# L3INIT_CM2 register map
Vendor: Texas Instruments
Peripheral module from a debugger description file (folder omap4460).
Registers are 32-bit, access per field, reset 0x70000 unless marked. A register's access mark holds for its fields unless they carry their own. Offsets are as the file gives them; lines under a group give offsets from that group; [hi:lo] are bit positions; {n}, {i} and the like mark numbered series; 'fields as' and 'values as' point back to an identical list; <NAME> marks a mode.

## L3INIT_CM2
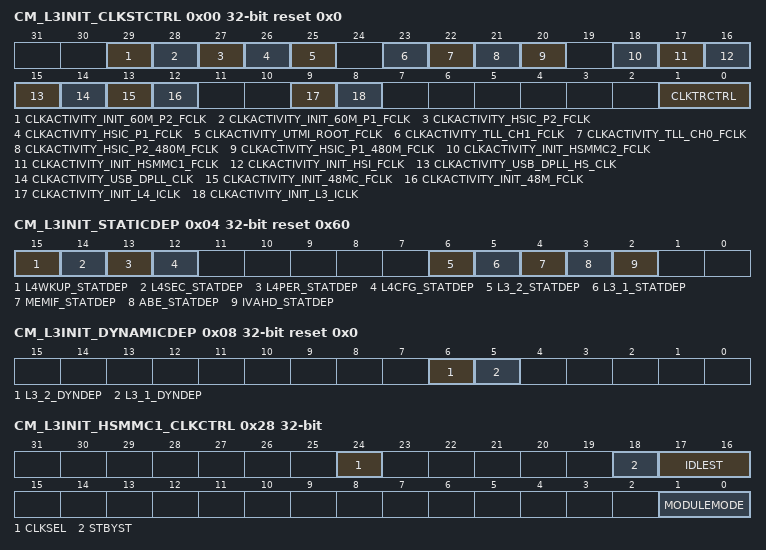
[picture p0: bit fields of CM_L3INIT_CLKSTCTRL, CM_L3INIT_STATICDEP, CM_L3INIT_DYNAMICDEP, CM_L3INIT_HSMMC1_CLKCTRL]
0x00 CM_L3INIT_CLKSTCTRL reset 0x0 — This register enables the domain power state transition. It controls the hardware supervised domain power state transition between ON-ACTIVE and ON-INACTIVE states. It also holds 1 status bit per clock input of the domain.
  [29] CLKACTIVITY_INIT_60M_P2_FCLK ro — This field indicates the state of the INIT_60M_P2_FCLK clock in the domain. [warm reset insensitive]
    0=CLKACTIVITY_INIT_60M_P2_FCLK_0_r (Corresponding clock is definitely gated); 1=CLKACTIVITY_INIT_60M_P2_FCLK_1_r (Corresponding clock is running or gating/ungating transition is ongoing)
  [28] CLKACTIVITY_INIT_60M_P1_FCLK ro — This field indicates the state of the INIT_60M_P1_FCLK clock in the domain. [warm reset insensitive]
    0=CLKACTIVITY_INIT_60M_P1_FCLK_0_r (Corresponding clock is definitely gated); 1=CLKACTIVITY_INIT_60M_P1_FCLK_1_r (Corresponding clock is running or gating/ungating transition is ongoing)
  [27] CLKACTIVITY_HSIC_P2_FCLK ro — This field indicates the state of the HSIC_P2_FCLK clock in the domain. [warm reset insensitive]
    0=CLKACTIVITY_HSIC_P2_FCLK_0_r (Corresponding clock is definitely gated); 1=CLKACTIVITY_HSIC_P2_FCLK_1_r (Corresponding clock is running or gating/ungating transition is ongoing)
  [26] CLKACTIVITY_HSIC_P1_FCLK ro — This field indicates the state of the HSIC_P1_FCLK clock in the domain. [warm reset insensitive]
    0=CLKACTIVITY_HSIC_P1_FCLK_0_r (Corresponding clock is definitely gated); 1=CLKACTIVITY_HSIC_P1_FCLK_1_r (Corresponding clock is running or gating/ungating transition is ongoing)
  [25] CLKACTIVITY_UTMI_ROOT_FCLK ro — This field indicates the state of the UTMI_ROOT_FCLK clock in the domain. [warm reset insensitive]
    0=CLKACTIVITY_UTMI_ROOT_FCLK_0_r (Corresponding clock is definitely gated); 1=CLKACTIVITY_UTMI_ROOT_FCLK_1_r (Corresponding clock is running or gating/ungating transition is ongoing)
  [23] CLKACTIVITY_TLL_CH1_FCLK ro — This field indicates the state of the TLL_CH1_FCLK clock in the domain. [warm reset insensitive]
    0=CLKACTIVITY_TLL_CH1_FCLK_0_r (Corresponding clock is definitely gated); 1=CLKACTIVITY_TLL_CH1_FCLK_1_r (Corresponding clock is running or gating/ungating transition is ongoing)
  [22] CLKACTIVITY_TLL_CH0_FCLK ro — This field indicates the state of the TLL_CH0_FCLK clock in the domain. [warm reset insensitive]
    0=CLKACTIVITY_TLL_CH0_FCLK_0_r (Corresponding clock is definitely gated); 1=CLKACTIVITY_TLL_CH0_FCLK_1_r (Corresponding clock is running or gating/ungating transition is ongoing)
  [21] CLKACTIVITY_HSIC_P2_480M_FCLK ro — This field indicates the state of the HSIC_P2_480M_FCLK clock in the domain. [warm reset insensitive]
    0=CLKACTIVITY_HSIC_P2_480M_FCLK_0_r (Corresponding clock is definitely gated); 1=CLKACTIVITY_HSIC_P2_480M_FCLK_1_r (Corresponding clock is running or gating/ungating transition is ongoing)
  [20] CLKACTIVITY_HSIC_P1_480M_FCLK ro — This field indicates the state of the HSIC_P1_480M_FCLK clock in the domain. [warm reset insensitive]
    0=CLKACTIVITY_HSIC_P1_480M_FCLK_0_r (Corresponding clock is definitely gated); 1=CLKACTIVITY_HSIC_P1_480M_FCLK_1_r (Corresponding clock is running or gating/ungating transition is ongoing)
  [18] CLKACTIVITY_INIT_HSMMC2_FCLK ro — This field indicates the state of the INIT_HSMMC2_FCLK clock in the domain. [warm reset insensitive]
    0=CLKACTIVITY_INIT_HSMMC2_FCLK_0_r (Corresponding clock is definitely gated); 1=CLKACTIVITY_INIT_HSMMC2_FCLK_1_r (Corresponding clock is running or gating/ungating transition is ongoing)
  [17] CLKACTIVITY_INIT_HSMMC1_FCLK ro — This field indicates the state of the INIT_HSMMC1_FCLK clock in the domain. [warm reset insensitive]
    0=CLKACTIVITY_INIT_HSMMC1_FCLK_0_r (Corresponding clock is definitely gated); 1=CLKACTIVITY_INIT_HSMMC1_FCLK_1_r (Corresponding clock is running or gating/ungating transition is ongoing)
  [16] CLKACTIVITY_INIT_HSI_FCLK ro — This field indicates the state of the INIT_HSI_FCLK clock in the domain. [warm reset insensitive]
    0=CLKACTIVITY_INIT_HSI_FCLK_0_r (Corresponding clock is definitely gated); 1=CLKACTIVITY_INIT_HSI_FCLK_1_r (Corresponding clock is running or gating/ungating transition is ongoing)
  [15] CLKACTIVITY_USB_DPLL_HS_CLK ro — This field indicates the state of the USB_DPLL_HS_CLK clock in the domain. [warm reset insensitive]
    0=CLKACTIVITY_USB_DPLL_HS_CLK_0_r (Corresponding clock is definitely gated); 1=CLKACTIVITY_USB_DPLL_HS_CLK_1_r (Corresponding clock is running or gating/ungating transition is ongoing)
  [14] CLKACTIVITY_USB_DPLL_CLK ro — This field indicates the state of the USB_DPLL_CLK clock in the domain. [warm reset insensitive]
    0=CLKACTIVITY_USB_DPLL_CLK_0_r (Corresponding clock is definitely gated); 1=CLKACTIVITY_USB_DPLL_CLK_1_r (Corresponding clock is running or gating/ungating transition is ongoing)
  [13] CLKACTIVITY_INIT_48MC_FCLK ro — This field indicates the state of the INIT_48MC_FCLK clock in the domain. [warm reset insensitive]
    0=CLKACTIVITY_INIT_48MC_FCLK_0_r (Corresponding clock is definitely gated); 1=CLKACTIVITY_INIT_48MC_FCLK_1_r (Corresponding clock is running or gating/ungating transition is ongoing)
  [12] CLKACTIVITY_INIT_48M_FCLK ro — This field indicates the state of the INIT_48M_FCLK clock in the domain. [warm reset insensitive]
    0=CLKACTIVITY_INIT_48M_FCLK_0_r (Corresponding clock is definitely gated); 1=CLKACTIVITY_INIT_48M_FCLK_1_r (Corresponding clock is running or gating/ungating transition is ongoing)
  [9] CLKACTIVITY_INIT_L4_ICLK ro — This field indicates the state of the L4_INIT_ICLK clock in the domain. [warm reset insensitive]
    0=CLKACTIVITY_INIT_L4_ICLK_0_r (Corresponding clock is definitely gated); 1=CLKACTIVITY_INIT_L4_ICLK_1_r (Corresponding clock is running or gating/ungating transition is ongoing)
  [8] CLKACTIVITY_INIT_L3_ICLK ro — This field indicates the state of the L3_INIT_ICLK clock in the domain. [warm reset insensitive]
    0=CLKACTIVITY_INIT_L3_ICLK_0_r (Corresponding clock is definitely gated); 1=CLKACTIVITY_INIT_L3_ICLK_1_r (Corresponding clock is running or gating/ungating transition is ongoing)
  [1:0] CLKTRCTRL rw — Controls the clock state transition of the L3INIT clock domain.
    0=NO_SLEEP: Sleep transition cannot be initiated. Wakeup transition may however occur.; 1=SW_SLEEP: Start a software forced sleep transition on the domain; 2=SW_WKUP: Start a software forced wake-up transition on the domain; 3=HW_AUTO: Automatic transition is enabled. Sleep and wakeup transition are based upon hardware conditions.
0x04 CM_L3INIT_STATICDEP access not given reset 0x60 — This register controls the static domain dependencies from L3INIT domain towards 'target' domains. It is relevant only for domain having system initiator(s).
  [15] L4WKUP_STATDEP rw — Static dependency towards L4WKUP clock domain
    0=Dependency is disabled; 1=Dependency is enabled
  [14] L4SEC_STATDEP rw — Static dependency towards L4SEC clock domain
    0=Dependency is disabled; 1=Dependency is enabled
  [13] L4PER_STATDEP rw — Static dependency towards L4PER clock domain
    0=Dependency is disabled; 1=Dependency is enabled
  [12] L4CFG_STATDEP rw — Static dependency towards L4CFG clock domain
    0=Dependency is disabled; 1=Dependency is enabled
  [6] L3_2_STATDEP — Static dependency towards L3_2 clock domain (access R Rreturns1s)
    1=L3_2_STATDEP_1_r (Dependency is enabled)
  [5] L3_1_STATDEP — Static dependency towards L3_1 clock domain (access R Rreturns1s)
    1=L3_1_STATDEP_1_r (Dependency is enabled)
  [4] MEMIF_STATDEP rw — Static dependency towards MEMIF clock domain
    0=Dependency is disabled; 1=Dependency is enabled
  [3] ABE_STATDEP rw — Static dependency towards ABE clock domain
    0=Dependency is disabled; 1=Dependency is enabled
  [2] IVAHD_STATDEP rw — Static dependency towards IVAHD clock domain
    0=Dependency is disabled; 1=Dependency is enabled
0x08 CM_L3INIT_DYNAMICDEP ro reset 0x0 — This register controls the dynamic domain depedencies from L3INIT domain towards 'target' domains. It is relevant only for domain having INTRCONN master port(s).
  [6] L3_2_DYNDEP — Dynamic dependency towards L3_2 clock domain
    0=L3_2_DYNDEP_0_r (Dependency is disabled)
  [5] L3_1_DYNDEP — Dynamic dependency towards L3_1 clock domain
    0=L3_1_DYNDEP_0_r (Dependency is disabled)
0x28 CM_L3INIT_HSMMC1_CLKCTRL — This register manages the MMC1 clocks.
  [24] CLKSEL rw — Selects the source of the functional clock.
    0=64MHz clock derived from DPLL_PER is selected; 1=96MHz clock derived from DPLL_PER is selected
  [18] STBYST ro — Module standby status. [warm reset insensitive]
    0=STBYST_0_r (Module is functional (not in standby)); 1=STBYST_1_r (Module is in standby)
  [17:16] IDLEST ro — Module idle status. [warm reset insensitive]
    0=IDLEST_0_r (Module is fully functional, including INTRCONN); 1=IDLEST_1_r (Module is performing transition: wakeup, or sleep, or sleep abortion); 2=IDLEST_2_r (Module is in idle mode (only INTRCONN part). It is functional if using separate functional clock); 3=IDLEST_3_r (Module is disabled and cannot be accessed)
  [1:0] MODULEMODE rw — Control the way mandatory clocks are managed.
    0=Module is disable by software. Any INTRCONN access to module results in an error, except if resulting from a module wakeup (asynchronous wakeup).; 1=MODULEMODE_1_r (Reserved); 2=Module is explicitly enabled. Interface clock (if not used for functions) may be gated according to the clock domain state. Functional clocks are guarantied to stay present. As long as in this configuration, power domain sleep transition cannot happen.; 3=MODULEMODE_3_r (Reserved)
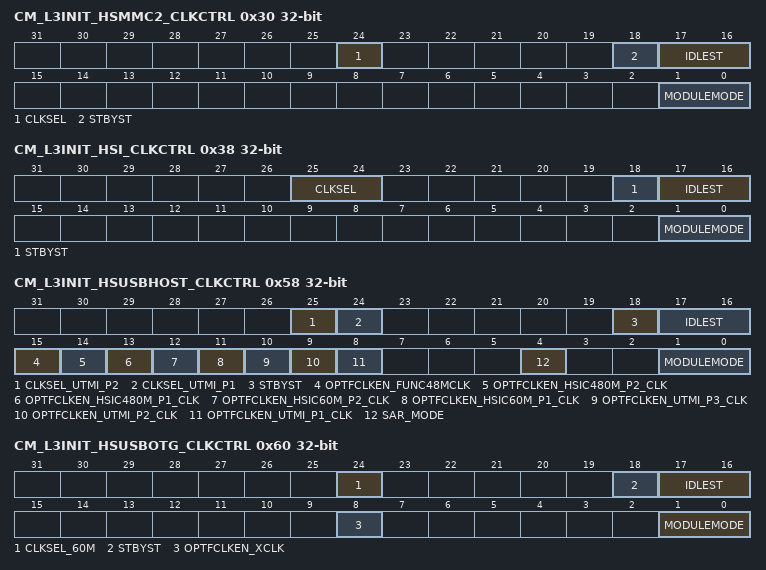
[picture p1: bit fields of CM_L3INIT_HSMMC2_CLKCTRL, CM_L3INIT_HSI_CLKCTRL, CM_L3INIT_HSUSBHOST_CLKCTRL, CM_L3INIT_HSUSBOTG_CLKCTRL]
0x30 CM_L3INIT_HSMMC2_CLKCTRL — This register manages the MMC2 clocks.
  fields as CM_L3INIT_HSMMC1_CLKCTRL
0x38 CM_L3INIT_HSI_CLKCTRL — This register manages the HSI clocks.
  [25:24] CLKSEL rw — Selects the functional clock source.
    0=HSI_FCLK is divide by 1 of 192-MHz clock, to be used for OPP100; 1=HSI_FCLK is divide by 2 of 192-MHz clock, to be used for OPP50; 2=HSI_FCLK is divide by 4 of 192-MHz clock
  [18] STBYST ro — Module standby status. [warm reset insensitive]
    values as CM_L3INIT_HSMMC1_CLKCTRL.STBYST
  [17:16] IDLEST ro — Module idle status. [warm reset insensitive]
    values as CM_L3INIT_HSMMC1_CLKCTRL.IDLEST
  [1:0] MODULEMODE rw — Control the way mandatory clocks are managed.Read 0x: Reserved .
    0=Module is disable by software. Any INTRCONN access to module results in an error, except if resulting from a module wakeup (asynchronous wakeup).; 1=Module is managed automatically by hardware according to clock domain; 3=MODULEMODE_3_r (Reserved)
0x58 CM_L3INIT_HSUSBHOST_CLKCTRL — This register manages the USB_HOST_HS clocks.
  [25] CLKSEL_UTMI_P2 rw — Selects the source of the functional clock for UTMI Port2 on USB Host
    0=The functional clock is provided by the internal clock source; 1=The functional clock is provided by an external PHY through an I/O pad
  [24] CLKSEL_UTMI_P1 rw — Selects the source of the functional clock for UTMI Por1 on USB Host
    values as CLKSEL_UTMI_P2
  [18] STBYST ro — Module standby status. [warm reset insensitive]
    values as CM_L3INIT_HSMMC1_CLKCTRL.STBYST
  [17:16] IDLEST ro — Module idle status. [warm reset insensitive]
    values as CM_L3INIT_HSMMC1_CLKCTRL.IDLEST
  [15] OPTFCLKEN_FUNC48MCLK rw — USB-HOST optional clock control: FUNC48MCLK
    0=Optional functional clock is disabled; 1=Optional functional clock is enabled
  [14] OPTFCLKEN_HSIC480M_P2_CLK rw — USB-HOST optional clock control: HSIC480M_P2_CLK
    values as OPTFCLKEN_FUNC48MCLK
  [13] OPTFCLKEN_HSIC480M_P1_CLK rw — USB-HOST optional clock control: HSIC480M_P1_CLK
    values as OPTFCLKEN_FUNC48MCLK
  [12] OPTFCLKEN_HSIC60M_P2_CLK rw — USB-HOST optional clock control: HSIC60M_P2_CLK
    values as OPTFCLKEN_FUNC48MCLK
  [11] OPTFCLKEN_HSIC60M_P1_CLK rw — USB-HOST optional clock control: HSIC60M_P1_CLK
    values as OPTFCLKEN_FUNC48MCLK
  [10] OPTFCLKEN_UTMI_P3_CLK rw — USB-HOST optional clock control: UTMI_P3_CLK
    values as OPTFCLKEN_FUNC48MCLK
  [9] OPTFCLKEN_UTMI_P2_CLK rw — USB-HOST optional clock control: UTMI_P2_CLK when CLKSEL_UTMI_P2 is 0
    values as OPTFCLKEN_FUNC48MCLK
  [8] OPTFCLKEN_UTMI_P1_CLK rw — USB-HOST optional clock control: UTMI_P1_CLK when CLKSEL_UTMI_P1 is 0
    values as OPTFCLKEN_FUNC48MCLK
  [4] SAR_MODE rw — SAR mode control for the module. Shall not be modify except if module is disabled.
    0=SAR mode is disabled; 1=SAR mode is enabled
  [1:0] MODULEMODE rw — Control the way mandatory clocks are managed.
    values as CM_L3INIT_HSMMC1_CLKCTRL.MODULEMODE
0x60 CM_L3INIT_HSUSBOTG_CLKCTRL — This register manages the USB_OTG_HS clocks.
  [24] CLKSEL_60M rw — Selects the source of the 60MHz functional clock.
    0=The 60MHz clock is sourced from on die UTMI PHY; 1=The 60MHz clock is sourced from the external ULPI PHY
  [18] STBYST ro — Module standby status. [warm reset insensitive]
    values as CM_L3INIT_HSMMC1_CLKCTRL.STBYST
  [17:16] IDLEST ro — Module idle status. [warm reset insensitive]
    values as CM_L3INIT_HSMMC1_CLKCTRL.IDLEST
  [8] OPTFCLKEN_XCLK rw — USB_OTG optional clock control: XCLK (60MHz clock)
    values as CM_L3INIT_HSUSBHOST_CLKCTRL.OPTFCLKEN_FUNC48MCLK
  [1:0] MODULEMODE rw — Control the way mandatory clocks are managed.
    0=Module is disable by software. Any INTRCONN access to module results in an error, except if resulting from a module wakeup (asynchronous wakeup).; 1=Module is managed automatically by hardware according to clock domain transition. A clock domain sleep transition put module into idle. A wakeup domain transition put it back into function. If CLKTRCTRL=3, any INTRCONN access to module is always granted. Module clocks may be gated according to the clock domain state.; 2=MODULEMODE_2_r (Reserved); 3=MODULEMODE_3_r (Reserved)
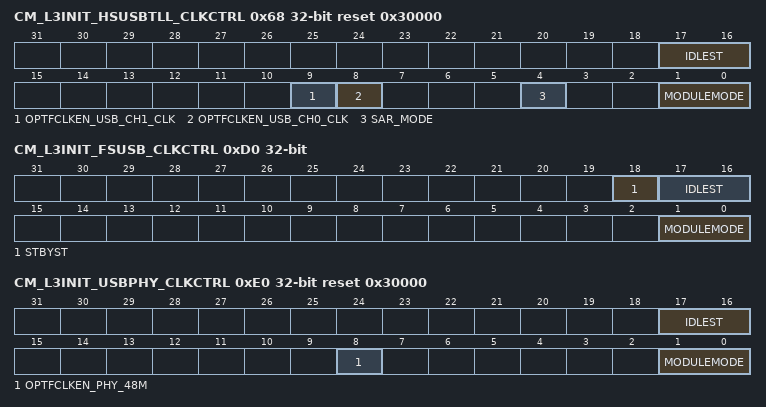
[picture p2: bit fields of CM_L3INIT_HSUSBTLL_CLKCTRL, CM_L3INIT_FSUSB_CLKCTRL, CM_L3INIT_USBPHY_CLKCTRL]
0x68 CM_L3INIT_HSUSBTLL_CLKCTRL reset 0x30000 — This register manages the USB_TLL clocks.
  [17:16] IDLEST ro — Module idle status. [warm reset insensitive]
    values as CM_L3INIT_HSMMC1_CLKCTRL.IDLEST
  [9] OPTFCLKEN_USB_CH1_CLK rw — USB-HOST optional clock control: USB_CH1_CLK
    values as CM_L3INIT_HSUSBHOST_CLKCTRL.OPTFCLKEN_FUNC48MCLK
  [8] OPTFCLKEN_USB_CH0_CLK rw — USB-HOST optional clock control: USB_CH0_CLK
    values as CM_L3INIT_HSUSBHOST_CLKCTRL.OPTFCLKEN_FUNC48MCLK
  [4] SAR_MODE rw — SAR mode control for the module. Shall not be modify except if module is disabled.
    0=SAR mode is disabled; 1=SAR mode is enabled
  [1:0] MODULEMODE rw — Control the way mandatory clocks are managed.
    values as CM_L3INIT_HSUSBOTG_CLKCTRL.MODULEMODE
0xD0 CM_L3INIT_FSUSB_CLKCTRL — This register manages the USB_HOST_FS clocks.
  [18] STBYST ro — Module standby status. [warm reset insensitive]
    values as CM_L3INIT_HSMMC1_CLKCTRL.STBYST
  [17:16] IDLEST ro — Module idle status. [warm reset insensitive]
    values as CM_L3INIT_HSMMC1_CLKCTRL.IDLEST
  [1:0] MODULEMODE rw — Control the way mandatory clocks are managed.
    values as CM_L3INIT_HSMMC1_CLKCTRL.MODULEMODE
0xE0 CM_L3INIT_USBPHY_CLKCTRL reset 0x30000 — This register manages the USBPHY clocks.
  [17:16] IDLEST ro — Module idle status. [warm reset insensitive]
    values as CM_L3INIT_HSMMC1_CLKCTRL.IDLEST
  [8] OPTFCLKEN_PHY_48M rw — USBPHY optional clock control: PHY_48M
    values as CM_L3INIT_HSUSBHOST_CLKCTRL.OPTFCLKEN_FUNC48MCLK
  [1:0] MODULEMODE rw — Control the way mandatory clocks are managed.
    values as CM_L3INIT_HSUSBOTG_CLKCTRL.MODULEMODE
